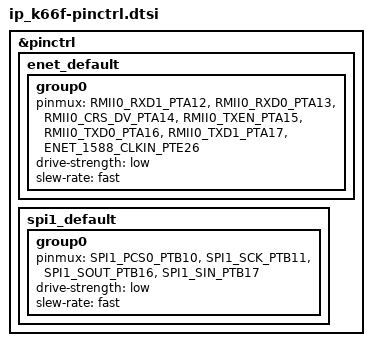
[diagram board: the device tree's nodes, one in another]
/*
 * NOTE: Autogenerated file by gen_board_pinctrl.py
 * for MK66FN2M0VMD18/signal_configuration.xml
 *
 * Copyright (c) 2022, NXP
 * SPDX-License-Identifier: Apache-2.0
 */


#include <nxp/kinetis/MK66FN2M0VMD18-pinctrl.h>

&pinctrl {
	enet_default: enet_default {
		group0 {
			pinmux = <RMII0_RXD1_PTA12>,
				<RMII0_RXD0_PTA13>,
				<RMII0_CRS_DV_PTA14>,
				<RMII0_TXEN_PTA15>,
				<RMII0_TXD0_PTA16>,
				<RMII0_TXD1_PTA17>,
				<ENET_1588_CLKIN_PTE26>;
			drive-strength = "low";
			slew-rate = "fast";
		};
	};

	spi1_default: spi1_default {
		group0 {
			pinmux = <SPI1_PCS0_PTB10>,
				<SPI1_SCK_PTB11>,
				<SPI1_SOUT_PTB16>,
				<SPI1_SIN_PTB17>;
			drive-strength = "low";
			slew-rate = "fast";
		};
	};

};
